# MK30D7 register map
File version: 1.6
Registers are 32-bit, read-write, reset 0x0 unless marked. A register's access mark holds for its fields unless they carry their own. Offsets are from the block's base; [hi:lo] are bit positions; {n}, {i} and the like mark numbered series.

## RFSYS — System register file
Base 0x40041000; register names take the prefix RFSYS_
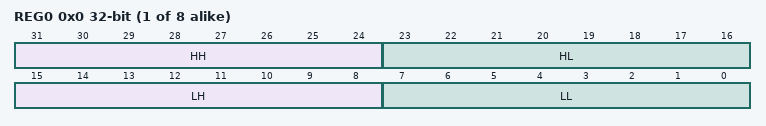
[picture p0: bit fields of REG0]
{0x0+4i} REG{i} (i=0..7) — Register file register
  [31:24] HH, [23:16] HL, [15:8] LH, [7:0] LL

## WDOG — Generation 2008 Watchdog Timer
Base 0x40052000; register names take the prefix WDOG_
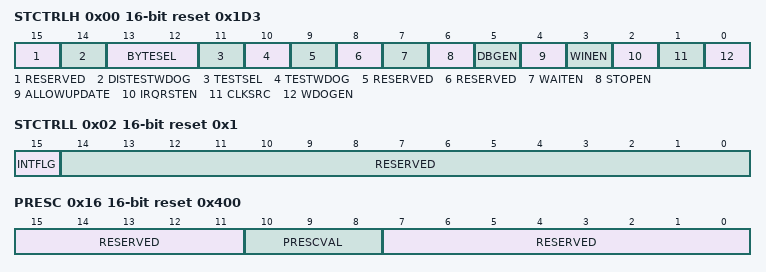
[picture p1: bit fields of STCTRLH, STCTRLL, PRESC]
0x00 STCTRLH 16-bit access per field reset 0x1D3 — Watchdog Status and Control Register High
  [15] RESERVED ro
  [14] DISTESTWDOG rw
    0=WDOG functional test mode is not disabled; 1=WDOG functional test mode is disabled permanently until reset
  [13:12] BYTESEL rw
    {v}=Byte {v} selected (v=0..3)
  [11] TESTSEL rw
    0=Quick test. The timer runs in normal operation. You can load a small time-out value to do a quick test.; 1=Byte test. Puts the timer in the byte test mode where individual bytes of the timer are enabled for operation and are compared for time-out against the corresponding byte of the programmed time-out value. Select the byte through BYTESEL[1:0] for testing.
  [10] TESTWDOG rw
  [9] RESERVED ro
  [8] RESERVED rw
  [7] WAITEN rw
    0=WDOG is disabled in CPU wait mode; 1=WDOG is enabled in CPU wait mode
  [6] STOPEN rw
    0=WDOG is disabled in CPU stop mode; 1=WDOG is enabled in CPU stop mode
  [5] DBGEN rw
    0=WDOG is disabled in CPU Debug mode; 1=WDOG is enabled in CPU Debug mode
  [4] ALLOWUPDATE rw
    0=No further updates allowed to WDOG write once registers; 1=WDOG write once registers can be unlocked for updating
  [3] WINEN rw
    0=Windowing mode is disabled; 1=Windowing mode is enabled
  [2] IRQRSTEN rw
    0=WDOG time-out generates reset only; 1=WDOG time-out initially generates an interrupt. After WCT time, it generates a reset.
  [1] CLKSRC rw
    0=Dedicated clock source selected as WDOG clock (LPO Oscillator); 1=WDOG clock sourced from alternate clock source
  [0] WDOGEN rw
    0=WDOG is disabled; 1=WDOG is enabled
0x02 STCTRLL 16-bit reset 0x1 — Watchdog Status and Control Register Low
  [15] INTFLG, [14:0] RESERVED
0x04 TOVALH 16-bit reset 0x4C — Watchdog Time-out Value Register High
  [15:0] TOVALHIGH
0x06 TOVALL 16-bit reset 0x4B4C — Watchdog Time-out Value Register Low
  [15:0] TOVALLOW
0x08 WINH 16-bit — Watchdog Window Register High
  [15:0] WINHIGH
0x0A WINL 16-bit reset 0x10 — Watchdog Window Register Low
  [15:0] WINLOW
0x0C REFRESH 16-bit reset 0xB480 — Watchdog Refresh Register
  [15:0] WDOGREFRESH
0x0E UNLOCK 16-bit reset 0xD928 — Watchdog Unlock Register
  [15:0] WDOGUNLOCK
0x10 TMROUTH 16-bit — Watchdog Timer Output Register High
  [15:0] TIMEROUTHIGH
0x12 TMROUTL 16-bit — Watchdog Timer Output Register Low
  [15:0] TIMEROUTLOW
0x14 RSTCNT 16-bit — Watchdog Reset Count Register
0x16 PRESC 16-bit access per field reset 0x400 — Watchdog Prescaler Register
  [15:11] RESERVED ro, [10:8] PRESCVAL rw, [7:0] RESERVED ro

## EWM — External Watchdog Monitor
Base 0x40061000; register names take the prefix EWM_
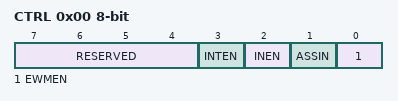
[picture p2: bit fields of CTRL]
0x00 CTRL 8-bit access per field — Control Register
  [7:4] RESERVED ro
  [3] INTEN rw — Interrupt Enable.
  [2] INEN rw — Input Enable.
  [1] ASSIN rw — EWM_in's Assertion State Select.
  [0] EWMEN rw — EWM enable.
0x01 SERV 8-bit wo — Service Register
  [7:0] SERVICE
0x02 CMPL 8-bit — Compare Low Register
  [7:0] COMPAREL
0x03 CMPH 8-bit reset 0xFF — Compare High Register
  [7:0] COMPAREH

## CMT — Carrier Modulator Transmitter
Base 0x40062000; register names take the prefix CMT_
0x00 CGH1 8-bit reset not defined — CMT Carrier Generator High Data Register 1
  [7:0] PH — Primary Carrier High Time Data Value
0x01 CGL1 8-bit reset not defined — CMT Carrier Generator Low Data Register 1
  [7:0] PL — Primary Carrier Low Time Data Value
0x02 CGH2 8-bit reset not defined — CMT Carrier Generator High Data Register 2
  [7:0] SH — Secondary Carrier High Time Data Value
0x03 CGL2 8-bit reset not defined — CMT Carrier Generator Low Data Register 2
  [7:0] SL — Secondary Carrier Low Time Data Value
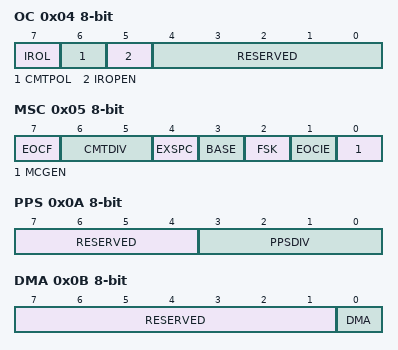
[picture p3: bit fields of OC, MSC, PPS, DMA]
0x04 OC 8-bit access per field — CMT Output Control Register
  [7] IROL rw — IRO Latch Control
  [6] CMTPOL rw — CMT Output Polarity
    0=CMT_IRO signal is active low; 1=CMT_IRO signal is active high
  [5] IROPEN rw — IRO Pin Enable
    0=CMT_IRO signal disabled; 1=CMT_IRO signal enabled as output
  [4:0] RESERVED ro
0x05 MSC 8-bit access per field — CMT Modulator Status and Control Register
  [7] EOCF ro — End Of Cycle Status Flag
    0=No end of modulation cycle occurrence since flag last cleared; 1=End of modulator cycle has occurred
  [6:5] CMTDIV rw — CMT Clock Divide Prescaler
    0=IF * 1; 1=IF * 2; 2=IF * 4; 3=IF * 8
  [4] EXSPC rw — Extended Space Enable
    0=Extended space disabled; 1=Extended space enabled
  [3] BASE rw — Baseband Enable
    0=Baseband mode disabled; 1=Baseband mode enabled
  [2] FSK rw — FSK Mode Select
    0=CMT operates in Time or Baseband mode; 1=CMT operates in FSK mode
  [1] EOCIE rw — End of Cycle Interrupt Enable
    0=CPU interrupt disabled; 1=CPU interrupt enabled
  [0] MCGEN rw — Modulator and Carrier Generator Enable
    0=Modulator and carrier generator disabled; 1=Modulator and carrier generator enabled
0x06 CMD1 8-bit reset not defined — CMT Modulator Data Register Mark High
  [7:0] MB
0x07 CMD2 8-bit reset not defined — CMT Modulator Data Register Mark Low
  [7:0] MB
0x08 CMD3 8-bit reset not defined — CMT Modulator Data Register Space High
  [7:0] SB
0x09 CMD4 8-bit reset not defined — CMT Modulator Data Register Space Low
  [7:0] SB
0x0A PPS 8-bit access per field — CMT Primary Prescaler Register
  [7:4] RESERVED ro
  [3:0] PPSDIV rw — Primary Prescaler Divider
    {v}=Bus Clock * {v+1} (v=0..15)
0x0B DMA 8-bit access per field — CMT Direct Memory Access
  [7:1] RESERVED ro
  [0] DMA rw — DMA Enable
    0=DMA transfer request and done are disabled; 1=DMA transfer request and done are enabled
